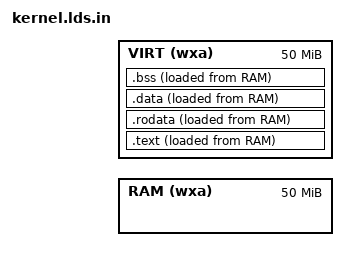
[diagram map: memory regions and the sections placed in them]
ENTRY({{KERNEL_LA_BASE}})
OUTPUT_ARCH(loongarch)
OUTPUT_FORMAT(
    "elf64-loongarch",
    "elf64-loongarch",
	"elf64-loongarch"
)

KERNEL_LA_BASE = {{KERNEL_LA_BASE}};
KERNEL_VA_BASE = {{KERNEL_VA_BASE}};

MEMORY {
    # kernel image is quite small, 50M should be rather enough for now
    RAM (wxa) : ORIGIN = KERNEL_LA_BASE, LENGTH = 50M
    VIRT (wxa) : ORIGIN = KERNEL_VA_BASE, LENGTH = 50M
}

SECTIONS {

    .text : ALIGN(4K) {
        __skernel = .;
        __stext = .;
        *(.text.bootstrap)
        *(.text .text.*)
        __etext = .;
    } > VIRT AT> RAM

    .rodata : ALIGN(4K) {
        __srodata = .;
        *(.rodata .rodata.*)
        *(.srodata .srodata.*)
        __skunit = .;
        *(.kunit .kunit.*)
        __ekunit = .;
        __erodata = .;
    }  > VIRT AT> RAM

    .data : ALIGN(4K) {
        __sdata = .;
        *(.data .data.*)
        *(.sdata .sdata.*)
        __spercpu = .;
        *(.percpu.core_local)
        *(.percpu)
        __epercpu = .;
        
        __sinitcall_driver = .;
        *(.initcall.driver .initcall.driver.*)
        __einitcall_driver = .;

        __edata = .;
    } > VIRT AT> RAM

    .bss : ALIGN(4K) {
        __sbss = .;
        *(.bss.stack0 .bss.bootstrap_heap)
        # other miscellaneous data in .bss section which should not be zero-initialized,
        # even though they may be actually zero in the beginning.
        *(.bss.nonzero_init .bss.nonzero_init.*) 
        __bss_zero_start = .;
        *(.bss .bss.*)
        *(.sbss .sbss.*)
        *(COMMON)
        __ebss = .;
    } > VIRT AT> RAM

    __ekernel = .;

    /DISCARD/ : {
        *(.eh_frame)
        *(.comment)
        *(.note.GNU-stack)
    }
}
